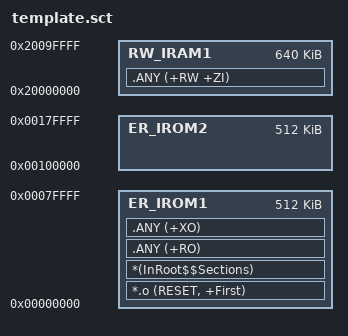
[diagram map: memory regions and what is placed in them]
; *************************************************************
; *** Scatter-Loading Description File generated by uVision ***
; *************************************************************

LR_IROM1 0x00000000 0x00080000  {    ; load region size_region
  ER_IROM1 0x00000000 0x00080000  {  ; load address = execution address
   *.o (RESET, +First)
   *(InRoot$$Sections)
   .ANY (+RO)
   .ANY (+XO)
  }
  RW_IRAM1 0x20000000 0x000A0000  {  ; RW data
   .ANY (+RW +ZI)
  }
  ;RW_IRAM2 0x21020000 UNINIT 0x00004000  {
  ;}
}


; Core1 image
LR_IROM2 0x00100000 0x00080000  {    ; load region size_region
  ER_IROM2 0x00100000 0x00080000  {  ; load address = execution address
   ;incbin_core1.* (+RO)
  }
}

; Core2 image
;LR_IROM3 0x000C0000 0x00040000  {    ; load region size_region
;  ER_IROM3 0x000C0000 0x00040000  {  ; load address = execution address
;   incbin_core2.* (+RO)
 ; }
;}






